AUTOSAR XML (schema 00054)
package /SwComponentTypes
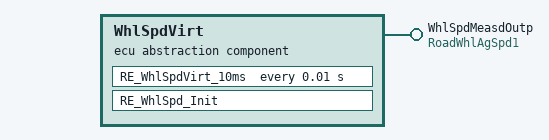
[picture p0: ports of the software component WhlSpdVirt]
  ecu abstraction sw component type WhlSpdVirt: hardware-element=IoAType
    provide port WhlSpdMeasdOutp: provided-interface=RoadWhlAgSpd1
    behavior WhlSpdVirt_IB: data-type-mapping=DataTypeMappingSet_AgSpd
      timing event TE_10ms: start-on-event=RE_WhlSpdVirt_10ms, period=0.01
      init event IE_WhlSpd_Init: start-on-event=RE_WhlSpd_Init
      runnable RE_WhlSpdVirt_10ms
        data-write-access:
          access DWA_WhlSpdMeasdOutp: accessed-variable=WhlSpdMeasdOutp.RoadWhlAgSpd
      runnable RE_WhlSpd_Init
